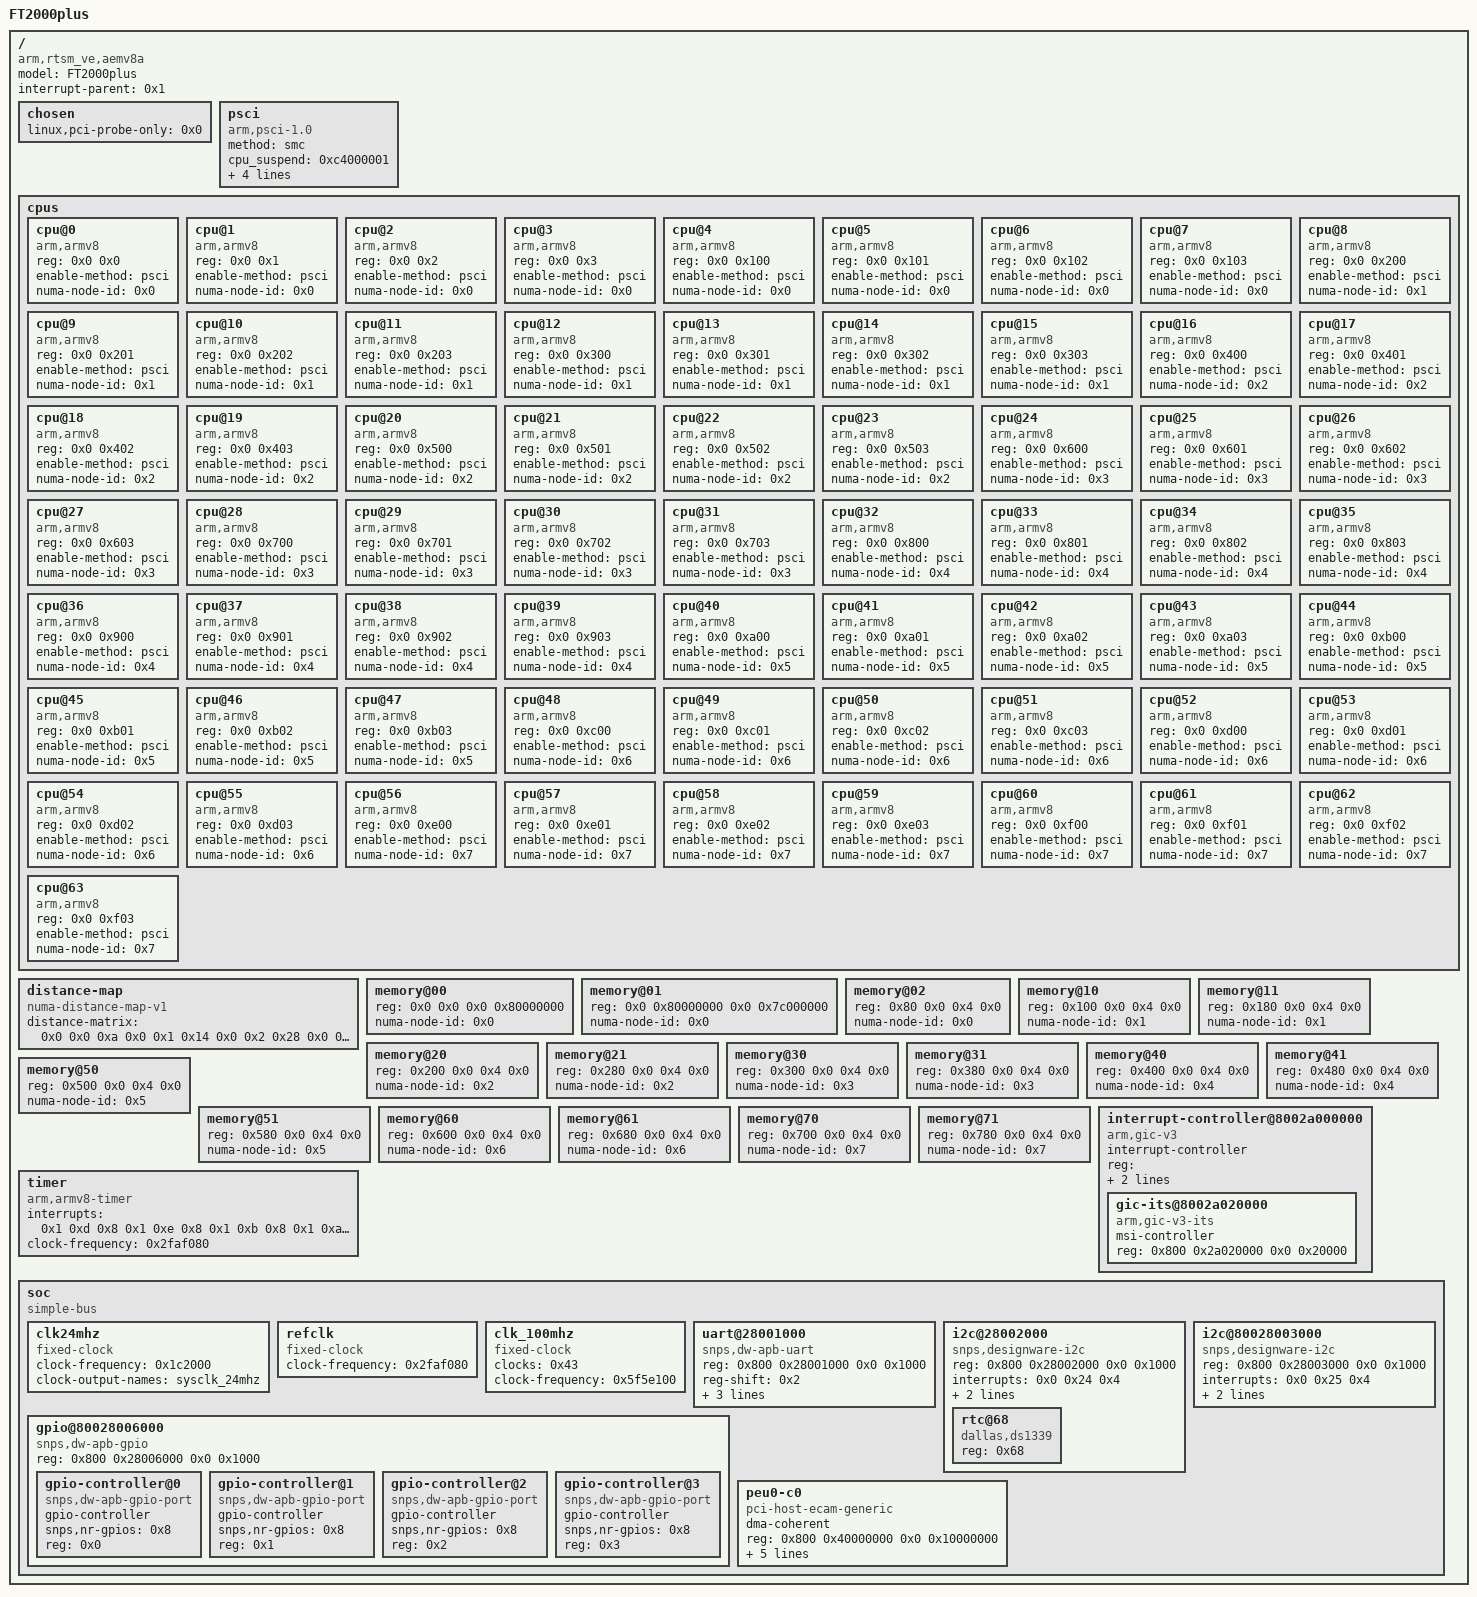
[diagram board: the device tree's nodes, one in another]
/dts-v1/;

/memreserve/	0x0000000080000000 0x0000000000010000;
/ {
	model = "FT2000plus";
	compatible = "arm,rtsm_ve,aemv8a", "arm,vexpress";
	interrupt-parent = <0x1>;
	#address-cells = <0x2>;
	#size-cells = <0x2>;

	chosen {
		linux,pci-probe-only = <0x0>;
	};

	psci {
		compatible = "arm,psci-1.0", "arm,psci-0.2", "arm,psci";
		method = "smc";
		cpu_suspend = <0xc4000001>;
		cpu_off = <0x84000002>;
		cpu_on = <0xc4000003>;
		sys_poweroff = <0x84000008>;
		sys_reset = <0x84000009>;
	};

	cpus {
		#address-cells = <0x2>;
		#size-cells = <0x0>;

		cpu@0 {
			device_type = "cpu";
			compatible = "arm,armv8";
			reg = <0x0 0x0>;
			enable-method = "psci";
			numa-node-id = <0x0>;
		};

		cpu@1 {
			device_type = "cpu";
			compatible = "arm,armv8";
			reg = <0x0 0x1>;
			enable-method = "psci";
			numa-node-id = <0x0>;
		};

		cpu@2 {
			device_type = "cpu";
			compatible = "arm,armv8";
			reg = <0x0 0x2>;
			enable-method = "psci";
			numa-node-id = <0x0>;
		};

		cpu@3 {
			device_type = "cpu";
			compatible = "arm,armv8";
			reg = <0x0 0x3>;
			enable-method = "psci";
			numa-node-id = <0x0>;
		};

		cpu@4 {
			device_type = "cpu";
			compatible = "arm,armv8";
			reg = <0x0 0x100>;
			enable-method = "psci";
			numa-node-id = <0x0>;
		};

		cpu@5 {
			device_type = "cpu";
			compatible = "arm,armv8";
			reg = <0x0 0x101>;
			enable-method = "psci";
			numa-node-id = <0x0>;
		};

		cpu@6 {
			device_type = "cpu";
			compatible = "arm,armv8";
			reg = <0x0 0x102>;
			enable-method = "psci";
			numa-node-id = <0x0>;
		};

		cpu@7 {
			device_type = "cpu";
			compatible = "arm,armv8";
			reg = <0x0 0x103>;
			enable-method = "psci";
			numa-node-id = <0x0>;
		};

		cpu@8 {
			device_type = "cpu";
			compatible = "arm,armv8";
			reg = <0x0 0x200>;
			enable-method = "psci";
			numa-node-id = <0x1>;
		};

		cpu@9 {
			device_type = "cpu";
			compatible = "arm,armv8";
			reg = <0x0 0x201>;
			enable-method = "psci";
			numa-node-id = <0x1>;
		};

		cpu@10 {
			device_type = "cpu";
			compatible = "arm,armv8";
			reg = <0x0 0x202>;
			enable-method = "psci";
			numa-node-id = <0x1>;
		};

		cpu@11 {
			device_type = "cpu";
			compatible = "arm,armv8";
			reg = <0x0 0x203>;
			enable-method = "psci";
			numa-node-id = <0x1>;
		};

		cpu@12 {
			device_type = "cpu";
			compatible = "arm,armv8";
			reg = <0x0 0x300>;
			enable-method = "psci";
			numa-node-id = <0x1>;
		};

		cpu@13 {
			device_type = "cpu";
			compatible = "arm,armv8";
			reg = <0x0 0x301>;
			enable-method = "psci";
			numa-node-id = <0x1>;
		};

		cpu@14 {
			device_type = "cpu";
			compatible = "arm,armv8";
			reg = <0x0 0x302>;
			enable-method = "psci";
			numa-node-id = <0x1>;
		};

		cpu@15 {
			device_type = "cpu";
			compatible = "arm,armv8";
			reg = <0x0 0x303>;
			enable-method = "psci";
			numa-node-id = <0x1>;
		};

		cpu@16 {
			device_type = "cpu";
			compatible = "arm,armv8";
			reg = <0x0 0x400>;
			enable-method = "psci";
			numa-node-id = <0x2>;
		};

		cpu@17 {
			device_type = "cpu";
			compatible = "arm,armv8";
			reg = <0x0 0x401>;
			enable-method = "psci";
			numa-node-id = <0x2>;
		};

		cpu@18 {
			device_type = "cpu";
			compatible = "arm,armv8";
			reg = <0x0 0x402>;
			enable-method = "psci";
			numa-node-id = <0x2>;
		};

		cpu@19 {
			device_type = "cpu";
			compatible = "arm,armv8";
			reg = <0x0 0x403>;
			enable-method = "psci";
			numa-node-id = <0x2>;
		};

		cpu@20 {
			device_type = "cpu";
			compatible = "arm,armv8";
			reg = <0x0 0x500>;
			enable-method = "psci";
			numa-node-id = <0x2>;
		};

		cpu@21 {
			device_type = "cpu";
			compatible = "arm,armv8";
			reg = <0x0 0x501>;
			enable-method = "psci";
			numa-node-id = <0x2>;
		};

		cpu@22 {
			device_type = "cpu";
			compatible = "arm,armv8";
			reg = <0x0 0x502>;
			enable-method = "psci";
			numa-node-id = <0x2>;
		};

		cpu@23 {
			device_type = "cpu";
			compatible = "arm,armv8";
			reg = <0x0 0x503>;
			enable-method = "psci";
			numa-node-id = <0x2>;
		};

		cpu@24 {
			device_type = "cpu";
			compatible = "arm,armv8";
			reg = <0x0 0x600>;
			enable-method = "psci";
			numa-node-id = <0x3>;
		};

		cpu@25 {
			device_type = "cpu";
			compatible = "arm,armv8";
			reg = <0x0 0x601>;
			enable-method = "psci";
			numa-node-id = <0x3>;
		};

		cpu@26 {
			device_type = "cpu";
			compatible = "arm,armv8";
			reg = <0x0 0x602>;
			enable-method = "psci";
			numa-node-id = <0x3>;
		};

		cpu@27 {
			device_type = "cpu";
			compatible = "arm,armv8";
			reg = <0x0 0x603>;
			enable-method = "psci";
			numa-node-id = <0x3>;
		};

		cpu@28 {
			device_type = "cpu";
			compatible = "arm,armv8";
			reg = <0x0 0x700>;
			enable-method = "psci";
			numa-node-id = <0x3>;
		};

		cpu@29 {
			device_type = "cpu";
			compatible = "arm,armv8";
			reg = <0x0 0x701>;
			enable-method = "psci";
			numa-node-id = <0x3>;
		};

		cpu@30 {
			device_type = "cpu";
			compatible = "arm,armv8";
			reg = <0x0 0x702>;
			enable-method = "psci";
			numa-node-id = <0x3>;
		};

		cpu@31 {
			device_type = "cpu";
			compatible = "arm,armv8";
			reg = <0x0 0x703>;
			enable-method = "psci";
			numa-node-id = <0x3>;
		};

		cpu@32 {
			device_type = "cpu";
			compatible = "arm,armv8";
			reg = <0x0 0x800>;
			enable-method = "psci";
			numa-node-id = <0x4>;
		};

		cpu@33 {
			device_type = "cpu";
			compatible = "arm,armv8";
			reg = <0x0 0x801>;
			enable-method = "psci";
			numa-node-id = <0x4>;
		};

		cpu@34 {
			device_type = "cpu";
			compatible = "arm,armv8";
			reg = <0x0 0x802>;
			enable-method = "psci";
			numa-node-id = <0x4>;
		};

		cpu@35 {
			device_type = "cpu";
			compatible = "arm,armv8";
			reg = <0x0 0x803>;
			enable-method = "psci";
			numa-node-id = <0x4>;
		};

		cpu@36 {
			device_type = "cpu";
			compatible = "arm,armv8";
			reg = <0x0 0x900>;
			enable-method = "psci";
			numa-node-id = <0x4>;
		};

		cpu@37 {
			device_type = "cpu";
			compatible = "arm,armv8";
			reg = <0x0 0x901>;
			enable-method = "psci";
			numa-node-id = <0x4>;
		};

		cpu@38 {
			device_type = "cpu";
			compatible = "arm,armv8";
			reg = <0x0 0x902>;
			enable-method = "psci";
			numa-node-id = <0x4>;
		};

		cpu@39 {
			device_type = "cpu";
			compatible = "arm,armv8";
			reg = <0x0 0x903>;
			enable-method = "psci";
			numa-node-id = <0x4>;
		};

		cpu@40 {
			device_type = "cpu";
			compatible = "arm,armv8";
			reg = <0x0 0xa00>;
			enable-method = "psci";
			numa-node-id = <0x5>;
		};

		cpu@41 {
			device_type = "cpu";
			compatible = "arm,armv8";
			reg = <0x0 0xa01>;
			enable-method = "psci";
			numa-node-id = <0x5>;
		};

		cpu@42 {
			device_type = "cpu";
			compatible = "arm,armv8";
			reg = <0x0 0xa02>;
			enable-method = "psci";
			numa-node-id = <0x5>;
		};

		cpu@43 {
			device_type = "cpu";
			compatible = "arm,armv8";
			reg = <0x0 0xa03>;
			enable-method = "psci";
			numa-node-id = <0x5>;
		};

		cpu@44 {
			device_type = "cpu";
			compatible = "arm,armv8";
			reg = <0x0 0xb00>;
			enable-method = "psci";
			numa-node-id = <0x5>;
		};

		cpu@45 {
			device_type = "cpu";
			compatible = "arm,armv8";
			reg = <0x0 0xb01>;
			enable-method = "psci";
			numa-node-id = <0x5>;
		};

		cpu@46 {
			device_type = "cpu";
			compatible = "arm,armv8";
			reg = <0x0 0xb02>;
			enable-method = "psci";
			numa-node-id = <0x5>;
		};

		cpu@47 {
			device_type = "cpu";
			compatible = "arm,armv8";
			reg = <0x0 0xb03>;
			enable-method = "psci";
			numa-node-id = <0x5>;
		};

		cpu@48 {
			device_type = "cpu";
			compatible = "arm,armv8";
			reg = <0x0 0xc00>;
			enable-method = "psci";
			numa-node-id = <0x6>;
		};

		cpu@49 {
			device_type = "cpu";
			compatible = "arm,armv8";
			reg = <0x0 0xc01>;
			enable-method = "psci";
			numa-node-id = <0x6>;
		};

		cpu@50 {
			device_type = "cpu";
			compatible = "arm,armv8";
			reg = <0x0 0xc02>;
			enable-method = "psci";
			numa-node-id = <0x6>;
		};

		cpu@51 {
			device_type = "cpu";
			compatible = "arm,armv8";
			reg = <0x0 0xc03>;
			enable-method = "psci";
			numa-node-id = <0x6>;
		};

		cpu@52 {
			device_type = "cpu";
			compatible = "arm,armv8";
			reg = <0x0 0xd00>;
			enable-method = "psci";
			numa-node-id = <0x6>;
		};

		cpu@53 {
			device_type = "cpu";
			compatible = "arm,armv8";
			reg = <0x0 0xd01>;
			enable-method = "psci";
			numa-node-id = <0x6>;
		};

		cpu@54 {
			device_type = "cpu";
			compatible = "arm,armv8";
			reg = <0x0 0xd02>;
			enable-method = "psci";
			numa-node-id = <0x6>;
		};

		cpu@55 {
			device_type = "cpu";
			compatible = "arm,armv8";
			reg = <0x0 0xd03>;
			enable-method = "psci";
			numa-node-id = <0x6>;
		};

		cpu@56 {
			device_type = "cpu";
			compatible = "arm,armv8";
			reg = <0x0 0xe00>;
			enable-method = "psci";
			numa-node-id = <0x7>;
		};

		cpu@57 {
			device_type = "cpu";
			compatible = "arm,armv8";
			reg = <0x0 0xe01>;
			enable-method = "psci";
			numa-node-id = <0x7>;
		};

		cpu@58 {
			device_type = "cpu";
			compatible = "arm,armv8";
			reg = <0x0 0xe02>;
			enable-method = "psci";
			numa-node-id = <0x7>;
		};

		cpu@59 {
			device_type = "cpu";
			compatible = "arm,armv8";
			reg = <0x0 0xe03>;
			enable-method = "psci";
			numa-node-id = <0x7>;
		};

		cpu@60 {
			device_type = "cpu";
			compatible = "arm,armv8";
			reg = <0x0 0xf00>;
			enable-method = "psci";
			numa-node-id = <0x7>;
		};

		cpu@61 {
			device_type = "cpu";
			compatible = "arm,armv8";
			reg = <0x0 0xf01>;
			enable-method = "psci";
			numa-node-id = <0x7>;
		};

		cpu@62 {
			device_type = "cpu";
			compatible = "arm,armv8";
			reg = <0x0 0xf02>;
			enable-method = "psci";
			numa-node-id = <0x7>;
		};

		cpu@63 {
			device_type = "cpu";
			compatible = "arm,armv8";
			reg = <0x0 0xf03>;
			enable-method = "psci";
			numa-node-id = <0x7>;
		};
	};

	distance-map {
		compatible = "numa-distance-map-v1";
		distance-matrix = <0x0 0x0 0xa 0x0 0x1 0x14 0x0 0x2 0x28 0x0 0x3 0x1e 0x0 0x4 0x14 0x0 0x5 0x1e 0x0 0x6 0x32 0x0 0x7 0x28 0x1 0x0 0x14 0x1 0x1 0xa 0x1 0x2 0x1e 0x1 0x3 0x14 0x1 0x4 0x1e 0x1 0x5 0x14 0x1 0x6 0x28 0x1 0x7 0x1e 0x2 0x0 0x28 0x2 0x1 0x1e 0x2 0x2 0xa 0x2 0x3 0x14 0x2 0x4 0x32 0x2 0x5 0x28 0x2 0x6 0x14 0x2 0x7 0x1e 0x3 0x0 0x1e 0x3 0x1 0x14 0x3 0x2 0x14 0x3 0x3 0xa 0x3 0x4 0x28 0x3 0x5 0x1e 0x3 0x6 0x1e 0x3 0x7 0x14 0x4 0x0 0x14 0x4 0x1 0x1e 0x4 0x2 0x32 0x4 0x3 0x28 0x4 0x4 0xa 0x4 0x5 0x14 0x4 0x6 0x28 0x4 0x7 0x1e 0x5 0x0 0x1e 0x5 0x1 0x14 0x5 0x2 0x28 0x5 0x3 0x1e 0x5 0x4 0x14 0x5 0x5 0xa 0x5 0x6 0x1e 0x5 0x7 0x14 0x6 0x0 0x32 0x6 0x1 0x28 0x6 0x2 0x14 0x6 0x3 0x1e 0x6 0x4 0x28 0x6 0x5 0x1e 0x6 0x6 0xa 0x6 0x7 0x14 0x7 0x0 0x28 0x7 0x1 0x1e 0x7 0x2 0x1e 0x7 0x3 0x14 0x7 0x4 0x1e 0x7 0x5 0x14 0x7 0x6 0x14 0x7 0x7 0xa>;
	};

	memory@00 {
		device_type = "memory";
		reg = <0x0 0x0 0x0 0x80000000>;
		numa-node-id = <0x0>;
	};

	memory@01 {
		device_type = "memory";
		reg = <0x0 0x80000000 0x0 0x7c000000>;
		numa-node-id = <0x0>;
	};

	memory@02 {
		device_type = "memory";
		reg = <0x80 0x0 0x4 0x0>;
		numa-node-id = <0x0>;
	};

	memory@10 {
		device_type = "memory";
		reg = <0x100 0x0 0x4 0x0>;
		numa-node-id = <0x1>;
	};

	memory@11 {
		device_type = "memory";
		reg = <0x180 0x0 0x4 0x0>;
		numa-node-id = <0x1>;
	};

	memory@20 {
		device_type = "memory";
		reg = <0x200 0x0 0x4 0x0>;
		numa-node-id = <0x2>;
	};

	memory@21 {
		device_type = "memory";
		reg = <0x280 0x0 0x4 0x0>;
		numa-node-id = <0x2>;
	};

	memory@30 {
		device_type = "memory";
		reg = <0x300 0x0 0x4 0x0>;
		numa-node-id = <0x3>;
	};

	memory@31 {
		device_type = "memory";
		reg = <0x380 0x0 0x4 0x0>;
		numa-node-id = <0x3>;
	};

	memory@40 {
		device_type = "memory";
		reg = <0x400 0x0 0x4 0x0>;
		numa-node-id = <0x4>;
	};

	memory@41 {
		device_type = "memory";
		reg = <0x480 0x0 0x4 0x0>;
		numa-node-id = <0x4>;
	};

	memory@50 {
		device_type = "memory";
		reg = <0x500 0x0 0x4 0x0>;
		numa-node-id = <0x5>;
	};

	memory@51 {
		device_type = "memory";
		reg = <0x580 0x0 0x4 0x0>;
		numa-node-id = <0x5>;
	};

	memory@60 {
		device_type = "memory";
		reg = <0x600 0x0 0x4 0x0>;
		numa-node-id = <0x6>;
	};

	memory@61 {
		device_type = "memory";
		reg = <0x680 0x0 0x4 0x0>;
		numa-node-id = <0x6>;
	};

	memory@70 {
		device_type = "memory";
		reg = <0x700 0x0 0x4 0x0>;
		numa-node-id = <0x7>;
	};

	memory@71 {
		device_type = "memory";
		reg = <0x780 0x0 0x4 0x0>;
		numa-node-id = <0x7>;
	};

	interrupt-controller@8002a000000 {
		compatible = "arm,gic-v3";
		#interrupt-cells = <0x3>;
		#address-cells = <0x2>;
		#size-cells = <0x2>;
		ranges;
		interrupt-controller;
		reg = <0x800 0x2a000000 0x0 0x10000 0x800 0x2a800000 0x0 0x800000 0x800 0x29c00000 0x0 0x10000 0x800 0x29c10000 0x0 0x10000 0x800 0x29c20000 0x0 0x10000>;
		interrupts = <0x1 0x9 0x4>;
		linux,phandle = <0x1>;
		phandle = <0x1>;

		gic-its@8002a020000 {
			compatible = "arm,gic-v3-its";
			msi-controller;
			reg = <0x800 0x2a020000 0x0 0x20000>;
			linux,phandle = <0x2>;
			phandle = <0x2>;
		};
	};

	timer {
		compatible = "arm,armv8-timer";
		interrupts = <0x1 0xd 0x8 0x1 0xe 0x8 0x1 0xb 0x8 0x1 0xa 0x8>;
		clock-frequency = <0x2faf080>;
	};

	soc {
		compatible = "simple-bus";
		#address-cells = <0x2>;
		#size-cells = <0x2>;
		ranges;

		clk24mhz {
			compatible = "fixed-clock";
			#clock-cells = <0x0>;
			clock-frequency = <0x1c2000>;
			clock-output-names = "sysclk_24mhz";
		};

		refclk {
			compatible = "fixed-clock";
			#clock-cells = <0x0>;
			clock-frequency = <0x2faf080>;
			linux,phandle = <0x43>;
			phandle = <0x43>;
		};

		clk_100mhz {
			compatible = "fixed-clock";
			#clock-cells = <0x0>;
			clocks = <0x43>;
			clock-frequency = <0x5f5e100>;
			linux,phandle = <0x44>;
			phandle = <0x44>;
		};

		uart@28001000 {
			compatible = "snps,dw-apb-uart";
			reg = <0x800 0x28001000 0x0 0x1000>;
			reg-shift = <0x2>;
			reg-io-width = <0x4>;
			interrupts = <0x0 0x23 0x4>;
			clock-frequency = <0x2faf080>;
			status = "ok";
		};

		i2c@28002000 {
			#address-cells = <0x1>;
			#size-cells = <0x0>;
			compatible = "snps,designware-i2c";
			reg = <0x800 0x28002000 0x0 0x1000>;
			interrupts = <0x0 0x24 0x4>;
			clock-frequency = <0x186a0>;
			clocks = <0x44>;
			status = "ok";

			rtc@68 {
				compatible = "dallas,ds1339";
				reg = <0x68>;
			};
        };

		i2c@80028003000 {
			#address-cells = <0x1>;
			#size-cells = <0x0>;
			compatible = "snps,designware-i2c";
			reg = <0x800 0x28003000 0x0 0x1000>;
			interrupts = <0x0 0x25 0x4>;
			clock-frequency = <0x186a0>;
			clocks = <0x44>;
			status = "ok";
		};

		gpio@80028006000 {
			compatible = "snps,dw-apb-gpio";
			reg = <0x800 0x28006000 0x0 0x1000>;
			#address-cells = <0x1>;
			#size-cells = <0x0>;
			status = "ok";

			gpio-controller@0 {
				compatible = "snps,dw-apb-gpio-port";
				gpio-controller;
				#gpio-cells = <0x2>;
				snps,nr-gpios = <0x8>;
				reg = <0x0>;
			};

			gpio-controller@1 {
				compatible = "snps,dw-apb-gpio-port";
				gpio-controller;
				#gpio-cells = <0x2>;
				snps,nr-gpios = <0x8>;
				reg = <0x1>;
			};

			gpio-controller@2 {
				compatible = "snps,dw-apb-gpio-port";
				gpio-controller;
				#gpio-cells = <0x2>;
				snps,nr-gpios = <0x8>;
				reg = <0x2>;
			};

			gpio-controller@3 {
				compatible = "snps,dw-apb-gpio-port";
				gpio-controller;
				#gpio-cells = <0x2>;
				snps,nr-gpios = <0x8>;
				reg = <0x3>;
			};
		
		};


		peu0-c0 {
			compatible = "pci-host-ecam-generic";
			device_type = "pci";
			#address-cells = <0x3>;
			#size-cells = <0x2>;
			#interrupt-cells = <0x1>;
			dma-coherent;
			reg = <0x800 0x40000000 0x0 0x10000000>;
			msi-parent = <0x2>;
			bus-range = <0x0 0xff>;
			interrupt-map-mask = <0x0 0x0 0x0 0x7>;
			interrupt-map = <0x0 0x0 0x0 0x1 0x1 0x0 0x0 0x0 0x33 0x4 0x0 0x0 0x0 0x2 0x1 0x0 0x0 0x0 0x34 0x4 0x0 0x0 0x0 0x3 0x1 0x0 0x0 0x0 0x35 0x4 0x0 0x0 0x0 0x4 0x1 0x0 0x0 0x0 0x36 0x4>;
			ranges = <0x1000000 0x0 0x0 0x800 0x50000000 0x0 0xf00000 0x2000000 0x0 0x60000000 0x800 0x60000000 0x0 0x20000000 0x3000000 0x20 0x0 0x820 0x0 0x20 0x0>;
		};
	};
};
